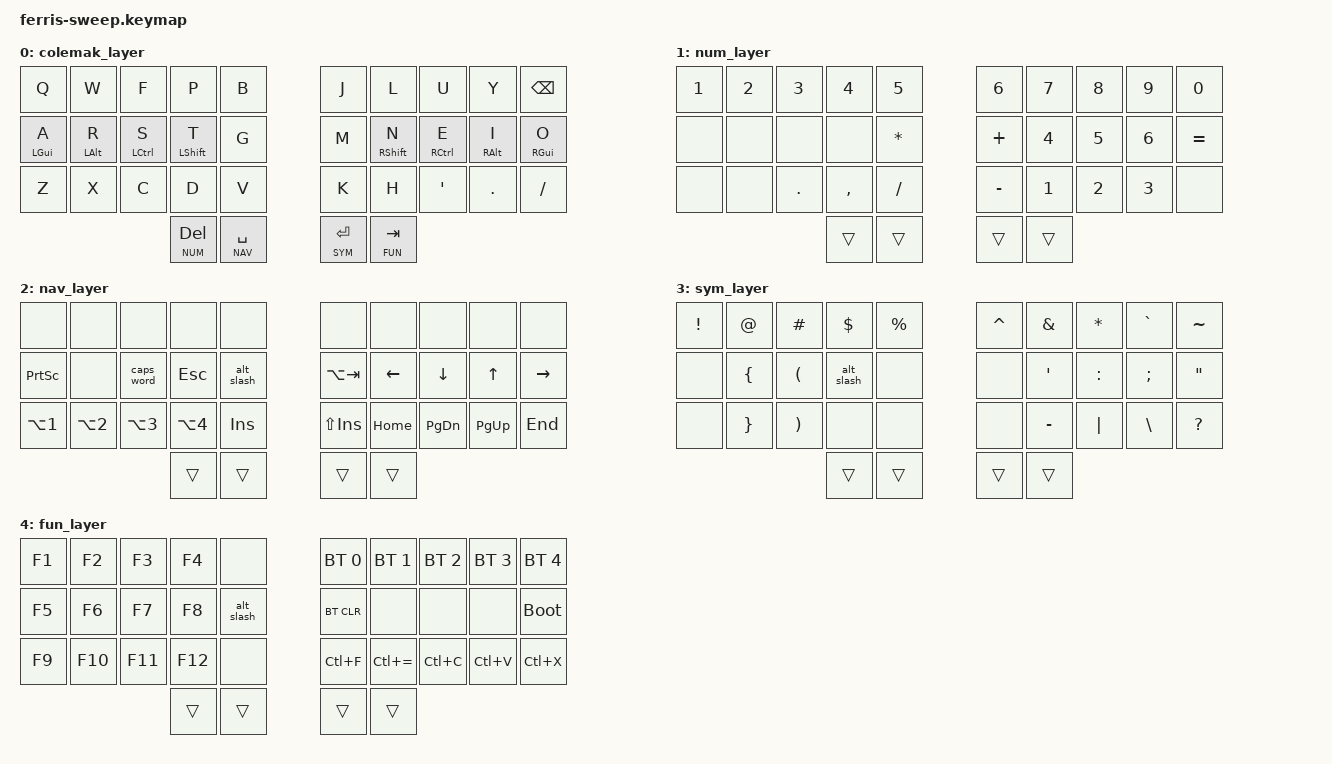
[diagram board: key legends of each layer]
#include <behaviors.dtsi>
#include <dt-bindings/zmk/keys.h>
#include <dt-bindings/zmk/bt.h>

#define COLEMAK 0
#define NUM     1
#define NAV     2
#define SYM     3
#define FUN     4

/ {
    macros {
        alt_slash: alt_slash {
            compatible = "zmk,behavior-macro";
            #binding-cells = <0>;
            bindings = <&macro_press &kp LALT>, <&macro_tap &kp FSLH>, <&macro_release &kp LALT>;
        };

        macro_work: macro_work {
            compatible = "zmk,behavior-macro";
            #binding-cells = <0>;
            bindings = <&none>; // Placeholder for your custom work macro string
        };
    };

    behaviors {
        hm: home_row_mods {
            compatible = "zmk,behavior-hold-tap";
            label = "HOME_ROW_MODS";
            #binding-cells = <2>;
            tapping-term-ms = <200>;
            quick-tap-ms = <0>;
            flavor = "balanced";
            bindings = <&kp>, <&kp>;
        };
    };

    keymap {
        compatible = "zmk,keymap";

        colemak_layer {
            // Colemak-DH Base
            bindings = <
                &kp Q        &kp W        &kp F        &kp P        &kp B         &kp J        &kp L        &kp U        &kp Y        &kp BSPC
                &hm LGUI A   &hm LALT R   &hm LCTL S   &hm LSHFT T  &kp G         &kp M        &hm RSHFT N  &hm RCTL E   &hm RALT I   &hm RGUI O
                &kp Z        &kp X        &kp C        &kp D        &kp V         &kp K        &kp H        &kp SQT      &kp DOT      &kp FSLH
                                     &lt NUM DEL   &lt NAV SPACE                 &lt SYM RET   &lt FUN TAB
            >;
        };

        num_layer {
            // Num Layer
            bindings = <
                &kp N1       &kp N2       &kp N3       &kp N4       &kp N5        &kp N6       &kp N7       &kp N8       &kp N9       &kp N0
                &none        &none        &none        &none        &kp STAR      &kp PLUS     &kp N4       &kp N5       &kp N6       &kp EQUAL
                &none        &none        &kp DOT      &kp COMMA    &kp FSLH      &kp MINUS    &kp N1       &kp N2       &kp N3       &none
                                          &trans       &trans                     &trans       &trans
            >;
        };

        nav_layer {
            // Nav Layer
            bindings = <
                &none        &none        &none        &none        &none         &none        &none        &none        &none        &none
                &kp PSCRN    &none        &caps_word   &kp ESC      &alt_slash    &kp LA(TAB)  &kp LEFT     &kp DOWN     &kp UP       &kp RIGHT
                &kp LA(N1)   &kp LA(N2)   &kp LA(N3)   &kp LA(N4)   &kp INS       &kp LS(INS)  &kp HOME     &kp PG_DN    &kp PG_UP    &kp END
                                          &trans       &trans                     &trans       &trans
            >;
        };

        sym_layer {
            // Sym Layer
            bindings = <
                &kp EXCL     &kp AT       &kp HASH     &kp DLLR     &kp PRCNT     &kp CARET    &kp AMPS     &kp STAR     &kp GRAVE    &kp TILDE
                &none        &kp LBRC     &kp LPAR     &alt_slash   &none         &none        &kp SQT      &kp COLON    &kp SEMI     &kp DQT
                &none        &kp RBRC     &kp RPAR     &none        &none         &none        &kp MINUS    &kp PIPE     &kp BSLH     &kp QMARK
                                          &trans       &trans                     &trans       &trans
            >;
        };

        fun_layer {
            // Fun Layer
            bindings = <
                &kp F1       &kp F2       &kp F3       &kp F4       &none         &bt BT_SEL 0 &bt BT_SEL 1 &bt BT_SEL 2 &bt BT_SEL 3 &bt BT_SEL 4
                &kp F5       &kp F6       &kp F7       &kp F8       &alt_slash    &bt BT_CLR   &none        &none        &none        &bootloader
                &kp F9       &kp F10      &kp F11      &kp F12      &none         &kp LC(F)    &kp LC(EQUAL)&kp LC(C)    &kp LC(V)    &kp LC(X)
                                          &trans       &trans                     &trans       &trans
            >;
        };
    };
};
